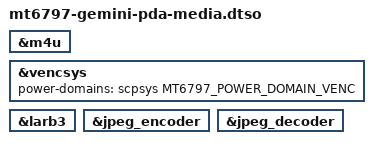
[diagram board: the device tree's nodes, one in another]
// SPDX-License-Identifier: (GPL-2.0-only OR MIT)
/*
 * Planet Computers Gemini PDA multimedia IOMMU and JPEG codec.
 *
 * Enables the MT6797 M4U for the JPEG encoder and decoder (larb3, VENC
 * power domain). The display stays untranslated: the board DTS removes its
 * iommus (see mt6797-gemini-pda.dts).
 */

/dts-v1/;
/plugin/;

#include <dt-bindings/power/mt6797-power.h>

&m4u {
	status = "okay";
};

/* VENC_CG is only accessible with the VENC power domain on. */
&vencsys {
	power-domains = <&scpsys MT6797_POWER_DOMAIN_VENC>;
};

&larb3 {
	status = "okay";
};

&jpeg_encoder {
	status = "okay";
};

&jpeg_decoder {
	status = "okay";
};
